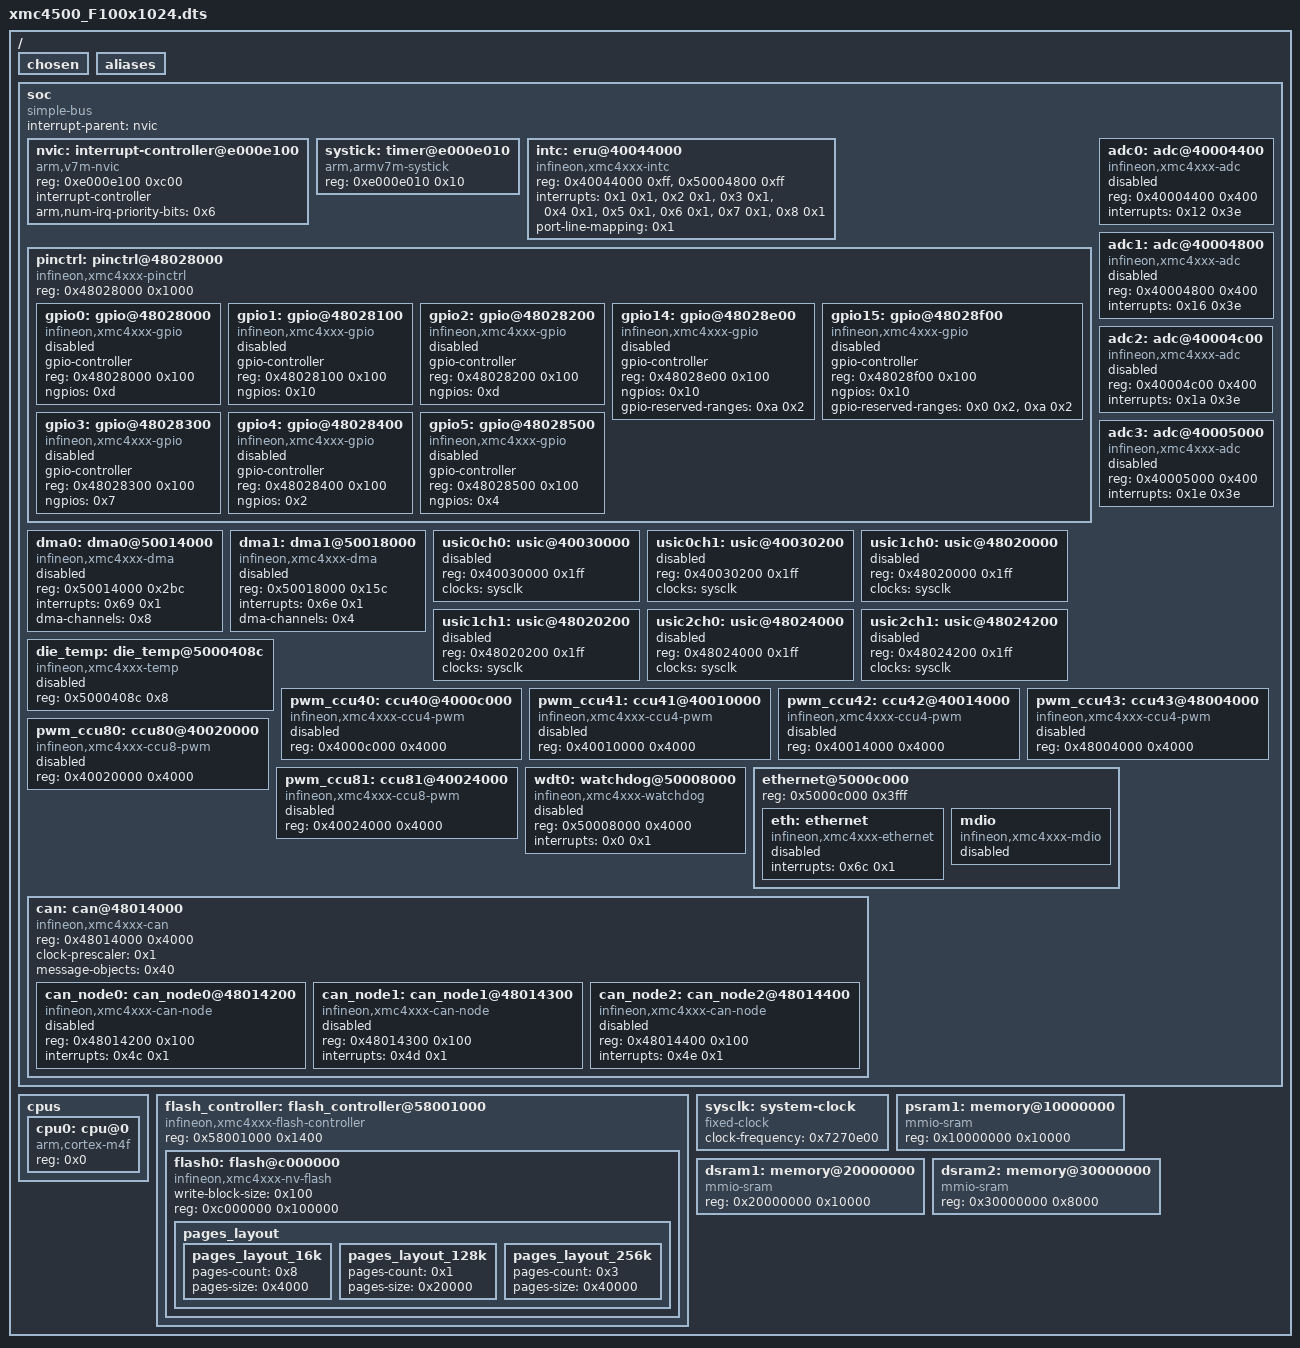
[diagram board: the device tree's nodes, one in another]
/dts-v1/;

/ {
	#address-cells = < 0x1 >;
	#size-cells = < 0x1 >;
	chosen {
	};
	aliases {
	};
	soc {
		#address-cells = < 0x1 >;
		#size-cells = < 0x1 >;
		compatible = "simple-bus";
		interrupt-parent = < &nvic >;
		ranges;
		nvic: interrupt-controller@e000e100 {
			#address-cells = < 0x1 >;
			compatible = "arm,v7m-nvic";
			reg = < 0xe000e100 0xc00 >;
			interrupt-controller;
			#interrupt-cells = < 0x2 >;
			arm,num-irq-priority-bits = < 0x6 >;
			phandle = < 0x1 >;
		};
		systick: timer@e000e010 {
			compatible = "arm,armv7m-systick";
			reg = < 0xe000e010 0x10 >;
		};
		intc: eru@40044000 {
			compatible = "infineon,xmc4xxx-intc";
			reg = < 0x40044000 0xff >, < 0x50004800 0xff >;
			reg-names = "eru1", "eru0";
			interrupts = < 0x1 0x1 >, < 0x2 0x1 >, < 0x3 0x1 >, < 0x4 0x1 >, < 0x5 0x1 >, < 0x6 0x1 >, < 0x7 0x1 >, < 0x8 0x1 >;
			interrupt-names = "eru0sr0", "eru0sr1", "eru0sr2", "eru0sr3", "eru1sr0", "eru1sr1", "eru1sr2", "eru1sr3";
			port-line-mapping = < 0x1 >;
		};
		pinctrl: pinctrl@48028000 {
			compatible = "infineon,xmc4xxx-pinctrl";
			reg = < 0x48028000 0x1000 >;
			#address-cells = < 0x1 >;
			#size-cells = < 0x1 >;
			gpio0: gpio@48028000 {
				compatible = "infineon,xmc4xxx-gpio";
				gpio-controller;
				#gpio-cells = < 0x2 >;
				reg = < 0x48028000 0x100 >;
				status = "disabled";
				ngpios = < 0xd >;
			};
			gpio1: gpio@48028100 {
				compatible = "infineon,xmc4xxx-gpio";
				gpio-controller;
				#gpio-cells = < 0x2 >;
				reg = < 0x48028100 0x100 >;
				status = "disabled";
				ngpios = < 0x10 >;
			};
			gpio2: gpio@48028200 {
				compatible = "infineon,xmc4xxx-gpio";
				gpio-controller;
				#gpio-cells = < 0x2 >;
				reg = < 0x48028200 0x100 >;
				status = "disabled";
				ngpios = < 0xd >;
			};
			gpio14: gpio@48028e00 {
				compatible = "infineon,xmc4xxx-gpio";
				gpio-controller;
				#gpio-cells = < 0x2 >;
				reg = < 0x48028e00 0x100 >;
				status = "disabled";
				ngpios = < 0x10 >;
				gpio-reserved-ranges = < 0xa 0x2 >;
			};
			gpio15: gpio@48028f00 {
				compatible = "infineon,xmc4xxx-gpio";
				gpio-controller;
				#gpio-cells = < 0x2 >;
				reg = < 0x48028f00 0x100 >;
				status = "disabled";
				ngpios = < 0x10 >;
				gpio-reserved-ranges = < 0x0 0x2 >, < 0xa 0x2 >;
			};
			gpio3: gpio@48028300 {
				compatible = "infineon,xmc4xxx-gpio";
				gpio-controller;
				#gpio-cells = < 0x2 >;
				reg = < 0x48028300 0x100 >;
				ngpios = < 0x7 >;
				status = "disabled";
			};
			gpio4: gpio@48028400 {
				compatible = "infineon,xmc4xxx-gpio";
				gpio-controller;
				#gpio-cells = < 0x2 >;
				reg = < 0x48028400 0x100 >;
				ngpios = < 0x2 >;
				status = "disabled";
			};
			gpio5: gpio@48028500 {
				compatible = "infineon,xmc4xxx-gpio";
				gpio-controller;
				#gpio-cells = < 0x2 >;
				reg = < 0x48028500 0x100 >;
				ngpios = < 0x4 >;
				status = "disabled";
			};
		};
		dma0: dma0@50014000 {
			compatible = "infineon,xmc4xxx-dma";
			reg = < 0x50014000 0x2bc >;
			interrupts = < 0x69 0x1 >;
			dma-channels = < 0x8 >;
			#dma-cells = < 0x3 >;
			status = "disabled";
		};
		dma1: dma1@50018000 {
			compatible = "infineon,xmc4xxx-dma";
			reg = < 0x50018000 0x15c >;
			interrupts = < 0x6e 0x1 >;
			dma-channels = < 0x4 >;
			#dma-cells = < 0x3 >;
			status = "disabled";
		};
		usic0ch0: usic@40030000 {
			reg = < 0x40030000 0x1ff >;
			clocks = < &sysclk >;
			status = "disabled";
		};
		usic0ch1: usic@40030200 {
			reg = < 0x40030200 0x1ff >;
			clocks = < &sysclk >;
			status = "disabled";
		};
		usic1ch0: usic@48020000 {
			reg = < 0x48020000 0x1ff >;
			clocks = < &sysclk >;
			status = "disabled";
		};
		usic1ch1: usic@48020200 {
			reg = < 0x48020200 0x1ff >;
			clocks = < &sysclk >;
			status = "disabled";
		};
		usic2ch0: usic@48024000 {
			reg = < 0x48024000 0x1ff >;
			clocks = < &sysclk >;
			status = "disabled";
		};
		usic2ch1: usic@48024200 {
			reg = < 0x48024200 0x1ff >;
			clocks = < &sysclk >;
			status = "disabled";
		};
		adc0: adc@40004400 {
			compatible = "infineon,xmc4xxx-adc";
			reg = < 0x40004400 0x400 >;
			interrupts = < 0x12 0x3e >;
			#io-channel-cells = < 0x1 >;
			status = "disabled";
		};
		adc1: adc@40004800 {
			compatible = "infineon,xmc4xxx-adc";
			reg = < 0x40004800 0x400 >;
			interrupts = < 0x16 0x3e >;
			#io-channel-cells = < 0x1 >;
			status = "disabled";
		};
		adc2: adc@40004c00 {
			compatible = "infineon,xmc4xxx-adc";
			reg = < 0x40004c00 0x400 >;
			interrupts = < 0x1a 0x3e >;
			#io-channel-cells = < 0x1 >;
			status = "disabled";
		};
		adc3: adc@40005000 {
			compatible = "infineon,xmc4xxx-adc";
			reg = < 0x40005000 0x400 >;
			interrupts = < 0x1e 0x3e >;
			#io-channel-cells = < 0x1 >;
			status = "disabled";
		};
		die_temp: die_temp@5000408c {
			reg = < 0x5000408c 0x8 >;
			compatible = "infineon,xmc4xxx-temp";
			status = "disabled";
		};
		pwm_ccu40: ccu40@4000c000 {
			compatible = "infineon,xmc4xxx-ccu4-pwm";
			reg = < 0x4000c000 0x4000 >;
			#pwm-cells = < 0x3 >;
			status = "disabled";
		};
		pwm_ccu41: ccu41@40010000 {
			compatible = "infineon,xmc4xxx-ccu4-pwm";
			reg = < 0x40010000 0x4000 >;
			#pwm-cells = < 0x3 >;
			status = "disabled";
		};
		pwm_ccu42: ccu42@40014000 {
			compatible = "infineon,xmc4xxx-ccu4-pwm";
			reg = < 0x40014000 0x4000 >;
			#pwm-cells = < 0x3 >;
			status = "disabled";
		};
		pwm_ccu43: ccu43@48004000 {
			compatible = "infineon,xmc4xxx-ccu4-pwm";
			reg = < 0x48004000 0x4000 >;
			#pwm-cells = < 0x3 >;
			status = "disabled";
		};
		pwm_ccu80: ccu80@40020000 {
			compatible = "infineon,xmc4xxx-ccu8-pwm";
			reg = < 0x40020000 0x4000 >;
			#pwm-cells = < 0x3 >;
			status = "disabled";
		};
		pwm_ccu81: ccu81@40024000 {
			compatible = "infineon,xmc4xxx-ccu8-pwm";
			reg = < 0x40024000 0x4000 >;
			#pwm-cells = < 0x3 >;
			status = "disabled";
		};
		wdt0: watchdog@50008000 {
			compatible = "infineon,xmc4xxx-watchdog";
			reg = < 0x50008000 0x4000 >;
			interrupts = < 0x0 0x1 >;
			status = "disabled";
		};
		ethernet@5000c000 {
			reg = < 0x5000c000 0x3fff >;
			eth: ethernet {
				compatible = "infineon,xmc4xxx-ethernet";
				interrupts = < 0x6c 0x1 >;
				status = "disabled";
			};
			mdio: mdio {
				compatible = "infineon,xmc4xxx-mdio";
				status = "disabled";
				#address-cells = < 0x1 >;
				#size-cells = < 0x0 >;
			};
		};
		can: can@48014000 {
			compatible = "infineon,xmc4xxx-can";
			reg = < 0x48014000 0x4000 >;
			clock-prescaler = < 0x1 >;
			#address-cells = < 0x1 >;
			#size-cells = < 0x1 >;
			message-objects = < 0x40 >;
			can_node0: can_node0@48014200 {
				compatible = "infineon,xmc4xxx-can-node";
				reg = < 0x48014200 0x100 >;
				interrupts = < 0x4c 0x1 >;
				status = "disabled";
			};
			can_node1: can_node1@48014300 {
				compatible = "infineon,xmc4xxx-can-node";
				reg = < 0x48014300 0x100 >;
				interrupts = < 0x4d 0x1 >;
				status = "disabled";
			};
			can_node2: can_node2@48014400 {
				compatible = "infineon,xmc4xxx-can-node";
				reg = < 0x48014400 0x100 >;
				interrupts = < 0x4e 0x1 >;
				status = "disabled";
			};
		};
	};
	cpus {
		#address-cells = < 0x1 >;
		#size-cells = < 0x0 >;
		cpu0: cpu@0 {
			compatible = "arm,cortex-m4f";
			reg = < 0x0 >;
		};
	};
	flash_controller: flash_controller@58001000 {
		compatible = "infineon,xmc4xxx-flash-controller";
		reg = < 0x58001000 0x1400 >;
		#address-cells = < 0x1 >;
		#size-cells = < 0x1 >;
		flash0: flash@c000000 {
			compatible = "infineon,xmc4xxx-nv-flash", "soc-nv-flash";
			write-block-size = < 0x100 >;
			reg = < 0xc000000 0x100000 >;
			pages_layout: pages_layout {
				pages_layout_16k: pages_layout_16k {
					pages-count = < 0x8 >;
					pages-size = < 0x4000 >;
				};
				pages_layout_128k: pages_layout_128k {
					pages-count = < 0x1 >;
					pages-size = < 0x20000 >;
				};
				pages_layout_256k: pages_layout_256k {
					pages-count = < 0x3 >;
					pages-size = < 0x40000 >;
				};
			};
		};
	};
	sysclk: system-clock {
		compatible = "fixed-clock";
		clock-frequency = < 0x7270e00 >;
		#clock-cells = < 0x0 >;
		phandle = < 0x2 >;
	};
	psram1: memory@10000000 {
		compatible = "mmio-sram";
		reg = < 0x10000000 0x10000 >;
	};
	dsram1: memory@20000000 {
		compatible = "mmio-sram";
		reg = < 0x20000000 0x10000 >;
	};
	dsram2: memory@30000000 {
		compatible = "mmio-sram";
		reg = < 0x30000000 0x8000 >;
	};
};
